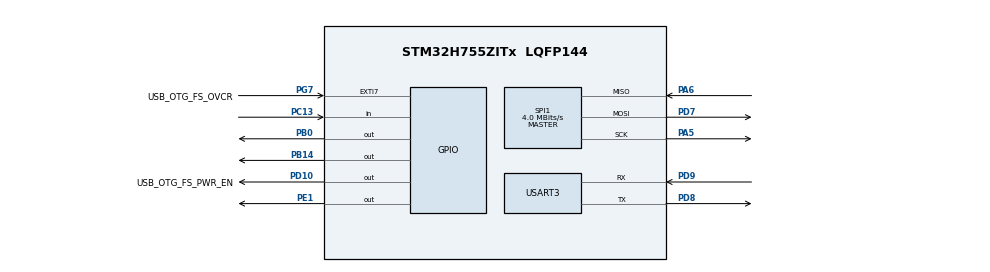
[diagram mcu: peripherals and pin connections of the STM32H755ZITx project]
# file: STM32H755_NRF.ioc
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CortexM4.IPs=FATFS_M4\:I,FREERTOS_M4\:I,IWDG2\:I,RCC,WWDG2\:I,DMA,BDMA,MDMA,NVIC2\:I,ETH,USART3,DEBUG,PDM2PCM_M4\:I,PWR,RESMGR_UTILITY,SYS_M4\:I,USB_DEVICE_M4\:I,USB_HOST_M4\:I,CORTEX_M4\:I,GPIO,OPENAMP_M4\:I,VREFBUF,NUCLEO-H755ZI-Q,SPI1
CortexM7.IPs=FATFS_M7\:I,FREERTOS_M7\:I,IWDG1\:I,RCC\:I,WWDG1\:I,DMA\:I,BDMA\:I,MDMA\:I,NVIC1\:I,ETH\:I,USART3\:I,USB_OTG_FS\:I,SYS\:I,CORTEX_M7\:I,DEBUG\:I,PDM2PCM_M7\:I,PWR\:I,RESMGR_UTILITY\:I,USB_DEVICE_M7\:I,USB_HOST_M7\:I,GPIO\:I,OPENAMP_M7\:I,VREFBUF\:I,NUCLEO-H755ZI-Q\:I,SPI1\:I
Mcu.Family=STM32H7
Mcu.Name=STM32H755ZITx
Mcu.Package=LQFP144
NVIC1.PriorityGroup=NVIC_PRIORITYGROUP_4
NVIC2.PriorityGroup=NVIC_PRIORITYGROUP_4
PA1.PinAttribute=CortexM7
PA1.Signal=ETH_REF_CLK
PA11.PinAttribute=CortexM7
PA11.Signal=USB_OTG_FS_DM
PA12.PinAttribute=CortexM7
PA12.Signal=USB_OTG_FS_DP
PA2.PinAttribute=CortexM7
PA2.Signal=ETH_MDIO
PA5.Mode=Full_Duplex_Master
PA5.PinAttribute=CortexM7
PA5.Signal=SPI1_SCK
PA6.Mode=Full_Duplex_Master
PA6.PinAttribute=CortexM7
PA6.Signal=SPI1_MISO
PA7.PinAttribute=CortexM7
PA7.Signal=ETH_CRS_DV
PA8.PinAttribute=CortexM7
PA8.Signal=USB_OTG_FS_SOF
PA9.PinAttribute=CortexM7
PA9.Signal=USB_OTG_FS_VBUS
PB0.PinAttribute=Free
PB0.Signal=GPIO_Output
PB13.PinAttribute=CortexM7
PB13.Signal=ETH_TXD1
PB14.PinAttribute=Free
PB14.Signal=GPIO_Output
PC1.PinAttribute=CortexM7
PC1.Signal=ETH_MDC
PC13.PinAttribute=Free
PC13.Signal=GPIO_Input
PC14-OSC32_IN\ (OSC32_IN).Mode=LSE-External-Oscillator
PC14-OSC32_IN\ (OSC32_IN).PinAttribute=Free
PC14-OSC32_IN\ (OSC32_IN).Signal=RCC_OSC32_IN
PC15-OSC32_OUT\ (OSC32_OUT).Mode=LSE-External-Oscillator
PC15-OSC32_OUT\ (OSC32_OUT).PinAttribute=Free
PC15-OSC32_OUT\ (OSC32_OUT).Signal=RCC_OSC32_OUT
PC4.PinAttribute=CortexM7
PC4.Signal=ETH_RXD0
PC5.PinAttribute=CortexM7
PC5.Signal=ETH_RXD1
PD10.GPIO_Label=USB_OTG_FS_PWR_EN
PD10.PinAttribute=Free
PD10.Signal=GPIO_Output
PD7.Mode=Full_Duplex_Master
PD7.PinAttribute=CortexM7
PD7.Signal=SPI1_MOSI
PD8.Mode=Asynchronous
PD8.PinAttribute=CortexM7
PD8.Signal=USART3_TX
PD9.Mode=Asynchronous
PD9.PinAttribute=CortexM7
PD9.Signal=USART3_RX
PE1.PinAttribute=Free
PE1.Signal=GPIO_Output
PG11.PinAttribute=CortexM7
PG11.Signal=ETH_TX_EN
PG13.PinAttribute=CortexM7
PG13.Signal=ETH_TXD0
PG7.GPIO_Label=USB_OTG_FS_OVCR
PG7.PinAttribute=Free
PG7.Signal=GPXTI7
PH0-OSC_IN\ (PH0).Mode=HSE-External-Clock-Source
PH0-OSC_IN\ (PH0).PinAttribute=Free
PH0-OSC_IN\ (PH0).Signal=RCC_OSC_IN
PH1-OSC_OUT\ (PH1).PinAttribute=Free
PH1-OSC_OUT\ (PH1).Signal=RCC_OSC_OUT
ProjectManager.HeapSize=M4-0x200,M7-0x200
ProjectManager.StackSize=M4-0x400,M7-0x400
ProjectManager.TargetToolchain=STM32CubeIDE
RCC.ADCFreq_Value=16125000
RCC.APB1Freq_Value=120000000
RCC.APB2Freq_Value=120000000
RCC.APB3Freq_Value=120000000
RCC.APB4Freq_Value=120000000
RCC.CortexFreq_Value=480000000
RCC.D1PPRE=RCC_APB3_DIV2
RCC.D2PPRE1=RCC_APB1_DIV2
RCC.D2PPRE2=RCC_APB2_DIV2
RCC.D3PPRE=RCC_APB4_DIV2
RCC.DIVM1=2
RCC.DIVN1=240
RCC.DIVQ1=5
RCC.HCLKFreq_Value=240000000
RCC.HPRE=RCC_HCLK_DIV2
RCC.HSE_VALUE=8000000
RCC.PLL2FRACN=0
RCC.PLL3FRACN=0
RCC.PLLFRACN=0
RCC.PLLSourceVirtual=RCC_PLLSOURCE_HSE
RCC.SPI123CLockSelection=RCC_SPI123CLKSOURCE_CLKP
RCC.SYSCLKFreq_VALUE=480000000
RCC.SYSCLKSource=RCC_SYSCLKSOURCE_PLLCLK
RCC.SupplySource=PWR_DIRECT_SMPS_SUPPLY
RCC.USBFreq_Value=192000000
SPI1.BaudRatePrescaler=SPI_BAUDRATEPRESCALER_16
SPI1.CalculateBaudRate=4.0 MBits/s
SPI1.DataSize=SPI_DATASIZE_8BIT
SPI1.Direction=SPI_DIRECTION_2LINES
SPI1.Mode=SPI_MODE_MASTER
SPI1.VirtualType=VM_MASTER
USART3.VirtualMode-Asynchronous=VM_ASYNC
VP_SYS_M4_VS_Systick.Mode=SysTick
board=NUCLEO-H755ZI-Q

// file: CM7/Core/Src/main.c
/* USER CODE BEGIN Header */
/**
  ******************************************************************************
  * @file           : main.c
  * @brief          : Main program body
  ******************************************************************************
  * @attention
  *
  * Copyright (c) 2024 STMicroelectronics.
  * All rights reserved.
  *
  * This software is licensed under terms that can be found in the LICENSE file
  * in the root directory of this software component.
  * If no LICENSE file comes with this software, it is provided AS-IS.
  *
  ******************************************************************************
  */
/* USER CODE END Header */
#include "main.h"

/* USER CODE BEGIN Includes */
#include "MY_NRF24.h"
/* USER CODE END Includes */

/* USER CODE BEGIN PD */

#ifndef HSEM_ID_0
#define HSEM_ID_0 (0U) /* HW semaphore 0*/
#endif

/* USER CODE END PD */

SPI_HandleTypeDef hspi1;

UART_HandleTypeDef huart3;

void SystemClock_Config(void);
void PeriphCommonClock_Config(void);
static void MX_GPIO_Init(void);
static void MX_SPI1_Init(void);
static void MX_USART3_UART_Init(void);

int main(void)
{

/* USER CODE BEGIN Boot_Mode_Sequence_0 */
  int32_t timeout;
/* USER CODE END Boot_Mode_Sequence_0 */

/* USER CODE BEGIN Boot_Mode_Sequence_1 */
  /* Wait until CPU2 boots and enters in stop mode or timeout*/
  timeout = 0xFFFF;
  while((__HAL_RCC_GET_FLAG(RCC_FLAG_D2CKRDY) != RESET) && (timeout-- > 0));
  if ( timeout < 0 )
  {
  Error_Handler();
  }
/* USER CODE END Boot_Mode_Sequence_1 */
  /* MCU Configuration--------------------------------------------------------*/

  /* Reset of all peripherals, Initializes the Flash interface and the Systick. */
  HAL_Init();

  /* Configure the system clock */
  SystemClock_Config();

  /* Configure the peripherals common clocks */
  PeriphCommonClock_Config();
/* USER CODE BEGIN Boot_Mode_Sequence_2 */
/* When system initialization is finished, Cortex-M7 will release Cortex-M4 by means of
HSEM notification */
/*HW semaphore Clock enable*/
__HAL_RCC_HSEM_CLK_ENABLE();
/*Take HSEM */
HAL_HSEM_FastTake(HSEM_ID_0);
/*Release HSEM in order to notify the CPU2(CM4)*/
HAL_HSEM_Release(HSEM_ID_0,0);
/* wait until CPU2 wakes up from stop mode */
timeout = 0xFFFF;
while((__HAL_RCC_GET_FLAG(RCC_FLAG_D2CKRDY) == RESET) && (timeout-- > 0));
if ( timeout < 0 )
{
Error_Handler();
}
/* USER CODE END Boot_Mode_Sequence_2 */

  /* Initialize all configured peripherals */
  MX_GPIO_Init();
  MX_SPI1_Init();
  MX_USART3_UART_Init();

  /* Infinite loop */
  while (1)
  {

  }
}

void SystemClock_Config(void)
{
  RCC_OscInitTypeDef RCC_OscInitStruct = {0};
  RCC_ClkInitTypeDef RCC_ClkInitStruct = {0};

  /** Supply configuration update enable
  */
  HAL_PWREx_ConfigSupply(PWR_DIRECT_SMPS_SUPPLY);

  /** Configure the main internal regulator output voltage
  */
  __HAL_PWR_VOLTAGESCALING_CONFIG(PWR_REGULATOR_VOLTAGE_SCALE0);

  while(!__HAL_PWR_GET_FLAG(PWR_FLAG_VOSRDY)) {}

  /** Initializes the RCC Oscillators according to the specified parameters
  * in the RCC_OscInitTypeDef structure.
  */
  RCC_OscInitStruct.OscillatorType = RCC_OSCILLATORTYPE_HSI|RCC_OSCILLATORTYPE_HSE;
  RCC_OscInitStruct.HSEState = RCC_HSE_BYPASS;
  RCC_OscInitStruct.HSIState = RCC_HSI_DIV1;
  RCC_OscInitStruct.HSICalibrationValue = RCC_HSICALIBRATION_DEFAULT;
  RCC_OscInitStruct.PLL.PLLState = RCC_PLL_ON;
  RCC_OscInitStruct.PLL.PLLSource = RCC_PLLSOURCE_HSE;
  RCC_OscInitStruct.PLL.PLLM = 2;
  RCC_OscInitStruct.PLL.PLLN = 240;
  RCC_OscInitStruct.PLL.PLLP = 2;
  RCC_OscInitStruct.PLL.PLLQ = 5;
  RCC_OscInitStruct.PLL.PLLR = 2;
  RCC_OscInitStruct.PLL.PLLRGE = RCC_PLL1VCIRANGE_2;
  RCC_OscInitStruct.PLL.PLLVCOSEL = RCC_PLL1VCOWIDE;
  RCC_OscInitStruct.PLL.PLLFRACN = 0;
  if (HAL_RCC_OscConfig(&RCC_OscInitStruct) != HAL_OK)
  {
    Error_Handler();
  }

  /** Initializes the CPU, AHB and APB buses clocks
  */
  RCC_ClkInitStruct.ClockType = RCC_CLOCKTYPE_HCLK|RCC_CLOCKTYPE_SYSCLK
                              |RCC_CLOCKTYPE_PCLK1|RCC_CLOCKTYPE_PCLK2
                              |RCC_CLOCKTYPE_D3PCLK1|RCC_CLOCKTYPE_D1PCLK1;
  RCC_ClkInitStruct.SYSCLKSource = RCC_SYSCLKSOURCE_PLLCLK;
  RCC_ClkInitStruct.SYSCLKDivider = RCC_SYSCLK_DIV1;
  RCC_ClkInitStruct.AHBCLKDivider = RCC_HCLK_DIV2;
  RCC_ClkInitStruct.APB3CLKDivider = RCC_APB3_DIV2;
  RCC_ClkInitStruct.APB1CLKDivider = RCC_APB1_DIV2;
  RCC_ClkInitStruct.APB2CLKDivider = RCC_APB2_DIV2;
  RCC_ClkInitStruct.APB4CLKDivider = RCC_APB4_DIV2;

  if (HAL_RCC_ClockConfig(&RCC_ClkInitStruct, FLASH_LATENCY_4) != HAL_OK)
  {
    Error_Handler();
  }
}

void PeriphCommonClock_Config(void)
{
  RCC_PeriphCLKInitTypeDef PeriphClkInitStruct = {0};

  /** Initializes the peripherals clock
  */
  PeriphClkInitStruct.PeriphClockSelection = RCC_PERIPHCLK_CKPER;
  PeriphClkInitStruct.CkperClockSelection = RCC_CLKPSOURCE_HSI;
  if (HAL_RCCEx_PeriphCLKConfig(&PeriphClkInitStruct) != HAL_OK)
  {
    Error_Handler();
  }
}

static void MX_SPI1_Init(void)
{

  /* SPI1 parameter configuration*/
  hspi1.Instance = SPI1;
  hspi1.Init.Mode = SPI_MODE_MASTER;
  hspi1.Init.Direction = SPI_DIRECTION_2LINES;
  hspi1.Init.DataSize = SPI_DATASIZE_8BIT;
  hspi1.Init.CLKPolarity = SPI_POLARITY_LOW;
  hspi1.Init.CLKPhase = SPI_PHASE_1EDGE;
  hspi1.Init.NSS = SPI_NSS_SOFT;
  hspi1.Init.BaudRatePrescaler = SPI_BAUDRATEPRESCALER_16;
  hspi1.Init.FirstBit = SPI_FIRSTBIT_MSB;
  hspi1.Init.TIMode = SPI_TIMODE_DISABLE;
  hspi1.Init.CRCCalculation = SPI_CRCCALCULATION_DISABLE;
  hspi1.Init.CRCPolynomial = 0x0;
  hspi1.Init.NSSPMode = SPI_NSS_PULSE_ENABLE;
  hspi1.Init.NSSPolarity = SPI_NSS_POLARITY_LOW;
  hspi1.Init.FifoThreshold = SPI_FIFO_THRESHOLD_01DATA;
  hspi1.Init.TxCRCInitializationPattern = SPI_CRC_INITIALIZATION_ALL_ZERO_PATTERN;
  hspi1.Init.RxCRCInitializationPattern = SPI_CRC_INITIALIZATION_ALL_ZERO_PATTERN;
  hspi1.Init.MasterSSIdleness = SPI_MASTER_SS_IDLENESS_00CYCLE;
  hspi1.Init.MasterInterDataIdleness = SPI_MASTER_INTERDATA_IDLENESS_00CYCLE;
  hspi1.Init.MasterReceiverAutoSusp = SPI_MASTER_RX_AUTOSUSP_DISABLE;
  hspi1.Init.MasterKeepIOState = SPI_MASTER_KEEP_IO_STATE_DISABLE;
  hspi1.Init.IOSwap = SPI_IO_SWAP_DISABLE;
  if (HAL_SPI_Init(&hspi1) != HAL_OK)
  {
    Error_Handler();
  }

}

static void MX_USART3_UART_Init(void)
{

  huart3.Instance = USART3;
  huart3.Init.BaudRate = 115200;
  huart3.Init.WordLength = UART_WORDLENGTH_8B;
  huart3.Init.StopBits = UART_STOPBITS_1;
  huart3.Init.Parity = UART_PARITY_NONE;
  huart3.Init.Mode = UART_MODE_TX_RX;
  huart3.Init.HwFlowCtl = UART_HWCONTROL_NONE;
  huart3.Init.OverSampling = UART_OVERSAMPLING_16;
  huart3.Init.OneBitSampling = UART_ONE_BIT_SAMPLE_DISABLE;
  huart3.Init.ClockPrescaler = UART_PRESCALER_DIV1;
  huart3.AdvancedInit.AdvFeatureInit = UART_ADVFEATURE_NO_INIT;
  if (HAL_UART_Init(&huart3) != HAL_OK)
  {
    Error_Handler();
  }
  if (HAL_UARTEx_SetTxFifoThreshold(&huart3, UART_TXFIFO_THRESHOLD_1_8) != HAL_OK)
  {
    Error_Handler();
  }
  if (HAL_UARTEx_SetRxFifoThreshold(&huart3, UART_RXFIFO_THRESHOLD_1_8) != HAL_OK)
  {
    Error_Handler();
  }
  if (HAL_UARTEx_DisableFifoMode(&huart3) != HAL_OK)
  {
    Error_Handler();
  }

}

static void MX_GPIO_Init(void)
{
  GPIO_InitTypeDef GPIO_InitStruct = {0};

  /* GPIO Ports Clock Enable */
  __HAL_RCC_GPIOC_CLK_ENABLE();
  __HAL_RCC_GPIOA_CLK_ENABLE();
  __HAL_RCC_GPIOB_CLK_ENABLE();
  __HAL_RCC_GPIOD_CLK_ENABLE();
  __HAL_RCC_GPIOG_CLK_ENABLE();

  /*Configure GPIO pins : PC1 PC4 PC5 */
  GPIO_InitStruct.Pin = GPIO_PIN_1|GPIO_PIN_4|GPIO_PIN_5;
  GPIO_InitStruct.Mode = GPIO_MODE_AF_PP;
  GPIO_InitStruct.Pull = GPIO_NOPULL;
  GPIO_InitStruct.Speed = GPIO_SPEED_FREQ_LOW;
  GPIO_InitStruct.Alternate = GPIO_AF11_ETH;
  HAL_GPIO_Init(GPIOC, &GPIO_InitStruct);

  /*Configure GPIO pins : PA1 PA2 PA7 */
  GPIO_InitStruct.Pin = GPIO_PIN_1|GPIO_PIN_2|GPIO_PIN_7;
  GPIO_InitStruct.Mode = GPIO_MODE_AF_PP;
  GPIO_InitStruct.Pull = GPIO_NOPULL;
  GPIO_InitStruct.Speed = GPIO_SPEED_FREQ_LOW;
  GPIO_InitStruct.Alternate = GPIO_AF11_ETH;
  HAL_GPIO_Init(GPIOA, &GPIO_InitStruct);

  /*Configure GPIO pin : PB13 */
  GPIO_InitStruct.Pin = GPIO_PIN_13;
  GPIO_InitStruct.Mode = GPIO_MODE_AF_PP;
  GPIO_InitStruct.Pull = GPIO_NOPULL;
  GPIO_InitStruct.Speed = GPIO_SPEED_FREQ_LOW;
  GPIO_InitStruct.Alternate = GPIO_AF11_ETH;
  HAL_GPIO_Init(GPIOB, &GPIO_InitStruct);

  /*Configure GPIO pins : PA8 PA11 PA12 */
  GPIO_InitStruct.Pin = GPIO_PIN_8|GPIO_PIN_11|GPIO_PIN_12;
  GPIO_InitStruct.Mode = GPIO_MODE_AF_PP;
  GPIO_InitStruct.Pull = GPIO_NOPULL;
  GPIO_InitStruct.Speed = GPIO_SPEED_FREQ_LOW;
  GPIO_InitStruct.Alternate = GPIO_AF10_OTG1_FS;
  HAL_GPIO_Init(GPIOA, &GPIO_InitStruct);

  /*Configure GPIO pins : PG11 PG13 */
  GPIO_InitStruct.Pin = GPIO_PIN_11|GPIO_PIN_13;
  GPIO_InitStruct.Mode = GPIO_MODE_AF_PP;
  GPIO_InitStruct.Pull = GPIO_NOPULL;
  GPIO_InitStruct.Speed = GPIO_SPEED_FREQ_LOW;
  GPIO_InitStruct.Alternate = GPIO_AF11_ETH;
  HAL_GPIO_Init(GPIOG, &GPIO_InitStruct);

}

void Error_Handler(void)
{
  __disable_irq();
  while (1)
  {
  }
}
